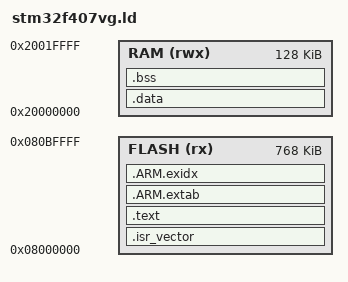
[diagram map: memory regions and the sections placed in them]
ENTRY(Reset_Handler)
MEMORY
{
  FLASH (rx) : ORIGIN = 0x08000000, LENGTH = 768K
  RAM (rwx) : ORIGIN = 0x20000000, LENGTH = 128K
}
SECTIONS {
  .isr_vector : { KEEP(*(.isr_vector)) } > FLASH
  .text : { *(.text*) *(.rodata*) *(.glue_7*) *(.vfp11_veneer) } > FLASH
  .ARM.extab : { *(.ARM.extab*) } > FLASH
  .ARM.exidx : { __exidx_start = .; *(.ARM.exidx*) __exidx_end = .; } > FLASH
  . = ALIGN(4);
  _etext = .;
  .data : AT(_etext) { . = ALIGN(4); _sdata = .; *(.data*) . = ALIGN(4); _edata = .; } > RAM
  .bss (NOLOAD) : { . = ALIGN(4); _sbss = .; *(.bss*) *(COMMON) . = ALIGN(4); _ebss = .; } > RAM
  . = ALIGN(8); _end = .; PROVIDE(end = .);
}
